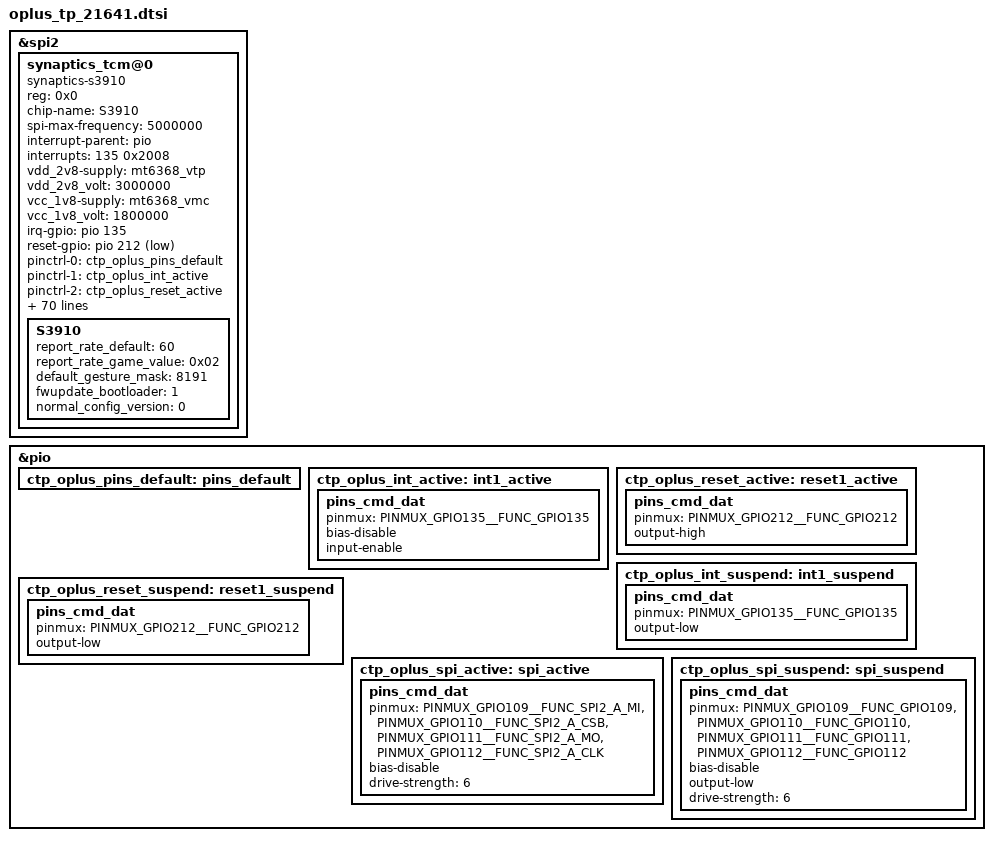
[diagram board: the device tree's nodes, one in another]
&spi2 {
	status = "okay";
	#address-cells = <1>;
	#size-cells = <0>;

	synaptics_tcm@0{
		compatible = "synaptics-s3910";
		reg = <0x0>;
		chip-name = "S3910";
		status = "okay";
		spi-max-frequency = <5000000>;
		/* Interrupt && Irq-gpio */
		interrupt-parent = <&pio>;
		interrupts = <135 0x2008>;

		/* Power Config */
		vdd_2v8-supply  = <&mt6368_vtp>;
		vdd_2v8_volt = <3000000>;
		vcc_1v8-supply  = <&mt6368_vmc>;
		vcc_1v8_volt = <1800000>;

		/* Other HW Resource */

		irq-gpio = <&pio 135 0x2008>;
		reset-gpio = <&pio 212 0x1>;
		//cs-gpio = <&pio 110 0x00>;

		pinctrl-names = "default",  "oplus_int_active",
		"oplus_reset_active", "oplus_int_suspend",
		"oplus_reset_suspend", "oplus_spi_active",
		"oplus_spi_suspend";
		pinctrl-0 = <&ctp_oplus_pins_default>;
		pinctrl-1 = <&ctp_oplus_int_active>;
		pinctrl-2 = <&ctp_oplus_reset_active>;
		pinctrl-3 = <&ctp_oplus_int_suspend>;
		pinctrl-4 = <&ctp_oplus_reset_suspend>;
		pinctrl-5 = <&ctp_oplus_spi_active>;
		pinctrl-6 = <&ctp_oplus_spi_suspend>;

		touchpanel,max-num-support = <10>;
		touchpanel,tx-rx-num = <16 36>;
		earsense,tx-rx-num = <17 18>;
		touchpanel,panel-coords = <4320 9648>;
		touchpanel,display-coords = <1080 2412>;
		touchpanel,touchmajor-limit = <128 216>;
		touchpanel,elimination-range = <20 200 200>;
		touchpanel,int-mode = <1>; /*0: interrupt and disable, 1:interrupt and not disable*/
		touchpanel,smooth-level = <0 1 2 4 7 9>;
		touchpanel,smooth-level-charging = <0 2 4 7 8 9>;
		touchpanel,sensitive-level = <0 70 55 40 25 10>;
		touchpanel,single-optimized-time = <8>;
		touchpanel,high-frame-rate-time = <60>;

		vid_len = <2>;
		/*touchpanel,tp_ic_type = <2>;*/
		panel_type = <3 7>; /*type:3 BOE type:7 TIANMA*/
		platform_support_project = <21641 21642 21649 0x216BE 0x216BF 0x216E6 0x216C6 0x216C7 0x216E5>;
		platform_support_project_dir = <21641 21641 21641 21641 21641 21641 21641 21641 21641>;
		platform_support_project_commandline = "oplus21641_boe_nt37701a_fhd_dsi_cmd_lcm_drv","oplus21641_tianma_ili7838a_fhd_dsi_cmd_lcm_drv";

		prevention,curved_screen_V2;
		prevention,grip_disable_level = <6>;
		prevention,updelay_time_ms = <45>;
		prevention,makeup_cnt_weight = <5 1 2 2 2>;
		prevention,large_corner_range = <480 1200>;
		prevention,large_corner_judge_condition = <850 100 400 7 7>;
		prevention,trx_reject_condition = <8 7 7>;
		prevention,trx_strict_reject_condition = <8 6 6>;
		prevention,large_judge_time_ms = <500 50 30>;
		prevention,large_exit_condition = <8 8 2>;
		prevention,single_channel_width = <160 160>;
		prevention,normal_tap_condition = <10 350>;
		prevention,long_edge_condition = <240 150 180 80>;
		prevention,long_strict_edge_condition = <160 60>;
		prevention,long_fingerhold_condition = <100 6 4 4>;
		prevention,short_edge_condition = <200 90 180 80>;
		prevention,short_strict_edge_condition = <160 60>;
		prevention,large_strict_exit_condition = <6 6>;
		prevention,top_corner_config = <250 750 100>;
		prevention,edge_swipe_config = <150 500>;

		/* SW Support Feature Control */
		black_gesture_support;
		sportify_aod_gesture_support;
		pressure_report_support;
		charger_pump_support;
		game_switch_support;
		smart_gesture_support;
		spi_port_support;
		fw_update_app_support;
	        fingerprint_underscreen_support;
		freq_hop_simulate_support;
		report_flow_unlock_support;
		screenoff_fingerprint_info_support;
		irq_need_dev_resume_ok;
		enable_point_auto_change;
		report_rate_white_list_support;
		kernel_grip_support;
		//grip_no_driver_support;
		health_monitor_support;
		black_gesture_indep_support;
		algorithm_support;
		snr_read_support;
		/*
		 *Virtual Key Config:
		 *1:touchpanel,button-type: <virtualkey_type  supportted_button-map>
		 *virtualkey_type:
		 *Type 1: using board_properties
		 *Type 2: using same IC (button zone&& touch zone are seprate)
		 *Type 3: using diffrent IC (button zone&& touch zone are seprate)
		 *Type 4: No need of virtual key process
		 *supportted_button-map:select|menu|home|back
		 *
		 *2:touchpanel,button-map
		 *type (X1,Y1)(X2,Y2)(X3,Y3)(Width_X,Hight_Y)--Only when button-type is 0
		 */
		touchpanel,button-type = <4>;
		touchpanel.button-TRx = <0 0>;

		S3910 {
			report_rate_default = <60>;
			report_rate_game_value = <0x02>;
			default_gesture_mask = <8191>;
			fwupdate_bootloader = <1>;
			normal_config_version = <0>; /* default config version has been changed to 2 in
				                       latest firmware and ic driver, old projects with
				                       old fw-cfg should config 0 in devicetrees */
		};
	};

};

&pio {
	ctp_oplus_pins_default: pins_default {
	};
	ctp_oplus_int_active: int1_active {
		pins_cmd_dat {
			pinmux = <PINMUX_GPIO135__FUNC_GPIO135>;
			bias-disable;
			input-enable;
		};
	};
	ctp_oplus_reset_active: reset1_active {
		pins_cmd_dat {
			pinmux = <PINMUX_GPIO212__FUNC_GPIO212>;
			output-high;
		};
	};
	ctp_oplus_int_suspend: int1_suspend {
		pins_cmd_dat {
			pinmux = <PINMUX_GPIO135__FUNC_GPIO135>;
			output-low;
		};
	};
	ctp_oplus_reset_suspend: reset1_suspend {
		pins_cmd_dat {
			pinmux = <PINMUX_GPIO212__FUNC_GPIO212>;
			output-low;
		};
	};
	ctp_oplus_spi_active: spi_active {
		pins_cmd_dat {
			pinmux = <PINMUX_GPIO109__FUNC_SPI2_A_MI>,
				<PINMUX_GPIO110__FUNC_SPI2_A_CSB>,
				<PINMUX_GPIO111__FUNC_SPI2_A_MO>,
				<PINMUX_GPIO112__FUNC_SPI2_A_CLK>;
			bias-disable;
			drive-strength = <6>;
		};
	};
	ctp_oplus_spi_suspend: spi_suspend {
		pins_cmd_dat {
			pinmux = < PINMUX_GPIO109__FUNC_GPIO109>,
				< PINMUX_GPIO110__FUNC_GPIO110>,
				<PINMUX_GPIO111__FUNC_GPIO111>,
				< PINMUX_GPIO112__FUNC_GPIO112>;
			bias-disable;
			output-low;
			drive-strength = <6>;
		};
	};
};
